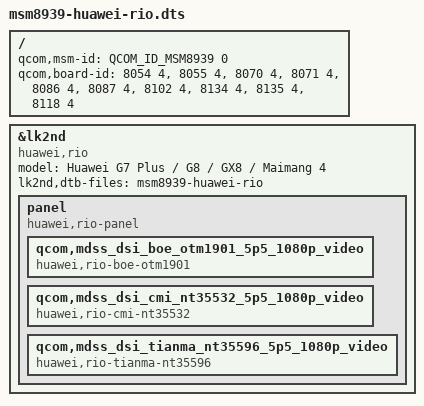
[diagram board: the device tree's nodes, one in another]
// SPDX-License-Identifier: BSD-3-Clause

#include <skeleton64.dtsi>
#include <lk2nd.dtsi>

/ {
	qcom,msm-id = <QCOM_ID_MSM8939 0>;
	qcom,board-id =
		<8054 4>, <8055 4>, <8070 4>, <8071 4>,
		<8086 4>, <8087 4>, <8102 4>, <8134 4>,
		<8135 4>, <8118 4>;
};

&lk2nd {
	model = "Huawei G7 Plus / G8 / GX8 / Maimang 4";
	compatible = "huawei,rio";

	lk2nd,dtb-files = "msm8939-huawei-rio";

	panel {
		compatible = "huawei,rio-panel", "lk2nd,panel";

		qcom,mdss_dsi_boe_otm1901_5p5_1080p_video {
			compatible = "huawei,rio-boe-otm1901";
		};
		qcom,mdss_dsi_cmi_nt35532_5p5_1080p_video {
			compatible = "huawei,rio-cmi-nt35532";
		};
		qcom,mdss_dsi_tianma_nt35596_5p5_1080p_video {
			compatible = "huawei,rio-tianma-nt35596";
		};
	};
};
